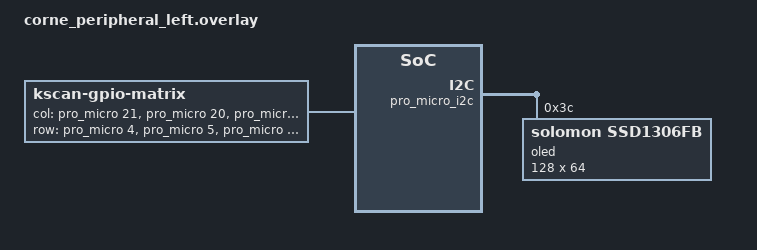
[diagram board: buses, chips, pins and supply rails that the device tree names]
/*
 * Copyright (c) 2020 Pete Johanson
 *
 * SPDX-License-Identifier: MIT
 */

#include "corne.dtsi"
#include "corne-layouts.dtsi"
#include "display_pinctrl.dtsi"

/ {
        chosen {
                zephyr,display = &oled;
                zmk,kscan = &kscan;
        };

        kscan: kscan {
               compatible = "zmk,kscan-gpio-matrix";
		diode-direction = "col2row";
                wakeup-source; 
                col-gpios
                = <&pro_micro 21 GPIO_ACTIVE_HIGH>
                , <&pro_micro 20 GPIO_ACTIVE_HIGH>
                , <&pro_micro 19 GPIO_ACTIVE_HIGH>
                , <&pro_micro 18 GPIO_ACTIVE_HIGH>
                , <&pro_micro 15 GPIO_ACTIVE_HIGH>
                , <&pro_micro 14 GPIO_ACTIVE_HIGH>
                ;

                row-gpios
                = <&pro_micro 4 (GPIO_ACTIVE_HIGH | GPIO_PULL_DOWN)>
                , <&pro_micro 5 (GPIO_ACTIVE_HIGH | GPIO_PULL_DOWN)>
                , <&pro_micro 6 (GPIO_ACTIVE_HIGH | GPIO_PULL_DOWN)>
                , <&pro_micro 7 (GPIO_ACTIVE_HIGH | GPIO_PULL_DOWN)>
                ;
        };
};

&pro_micro_i2c {
    compatible = "nordic,nrf-twim";
    status = "okay";
    pinctrl-0 = <&i2c0_default>;
    pinctrl-1 = <&i2c0_sleep>;
    pinctrl-names = "default", "sleep";

    oled: ssd1306@3c {
        compatible = "solomon,ssd1306fb";
        reg = <0x3c>;
        width = <128>;
        height = <64>;
        segment-offset = <0>;
        page-offset = <0>;
        display-offset = <0>;
        multiplex-ratio = <63>;
        segment-remap;
        com-invdir;
        inversion-on;
        prechargep = <0x22>;
    };
};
